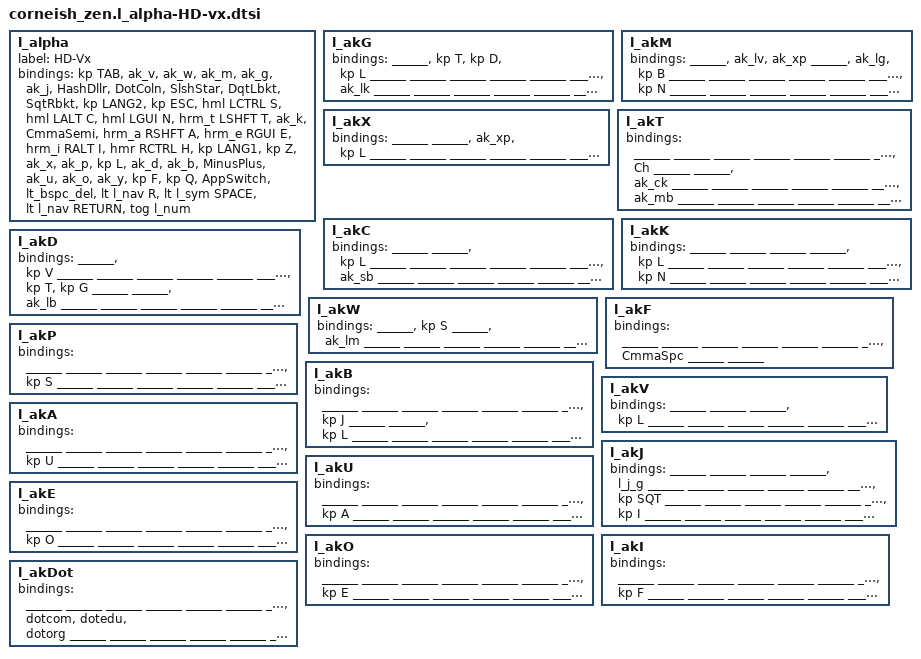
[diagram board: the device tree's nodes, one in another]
#define ______  &trans

/*  Base (alpha) Layer  Hands Down Vibranium-vb
        for 36 keys on a board with 42 keys
        ╭─────────────────────╮ ╭──────────────────────╮
esc     │  V   W   M   G   J  │ │  #$  .:  /*  "[  ']  │ LANG2/henk
tab     │  S   C   N   T   K  | |  ,;   A   E   I   H  │ LANG1/mhen
 Z      │  X   P   L   D   B  │ │  -+   U   O   Y   F  │  Q
        ╰────╮    App BSP  R  │ │  SPC RET Tg(Num)╭────╯
             ╰────────────────╯ ╰─────────────────╯
*/


                l_alpha {
                        label = "HD-Vx";
                        bindings = <
&kp TAB  &ak_v   &ak_w   &ak_m   &ak_g   &ak_j                          &HashDllr   &DotColn    &SlshStar   &DqtLbkt   &SqtRbkt &kp LANG2
&kp ESC &hml LCTRL S &hml LALT C   &hml LGUI N  &hrm_t LSHFT T &ak_k    &CmmaSemi   &hrm_a RSHFT A &hrm_e RGUI E  &hrm_i RALT I  &hmr RCTRL H &kp LANG1
&kp Z   &ak_x   &ak_p   &kp L   &ak_d   &ak_b                           &MinusPlus  &ak_u       &ak_o       &ak_y      &kp F    &kp Q
                        &AppSwitch &lt_bspc_del &lt l_nav R             &lt l_sym SPACE &lt l_nav RETURN  &tog l_num
                        >;
                };

                   l_akG {
                            bindings = <
______   &kp T    &kp D    &kp L    ______   ______       ______   ______   ______   ______   ______   ______
______   ______   ______   ______   ______   &ak_lk       ______   ______   ______   ______   ______   ______
______   ______   ______   ______   ______   ______       ______   ______   ______   ______   ______   ______
                           ______   ______   ______       ______   ______   ______
                            >;
                   };
                   l_akM {
                            bindings = <
______   &ak_lv   &ak_xp   ______   &ak_lg   &kp B        ______   ______   ______   ______   ______   ______
______   ______   ______   ______   ______   ______       ______   ______   ______   ______   &kp N    ______
______   ______   ______   ______   ______   ______       ______   ______   ______   ______   ______   ______
                           ______   ______   ______       ______   ______   ______
                            >;
                   };
                   l_akX {
                            bindings = <
______   ______   &ak_xp   &kp L    ______   ______       ______   ______   ______   ______   ______   ______
______   ______   ______   ______   ______   ______       ______   ______   ______   ______   ______   ______
______   ______   ______   ______   ______   ______       ______   ______   ______   ______   ______   ______
                           ______   ______   ______       ______   ______   ______
                            >;
                   };
                   l_akT {
                            bindings = <
______   ______   ______   ______   ______   ______       ______   ______   ______   ______   ______   ______
______   ______   &Ch      ______   ______   &ak_ck       ______   ______   ______   ______   ______   ______
______   ______   ______   ______   ______   &ak_mb       ______   ______   ______   ______   ______   ______
                           ______   ______   ______       ______   ______   ______
                            >;
                   };
                l_akC {
                        bindings = <
______   ______   &kp L    ______   ______   ______       ______   ______   ______   ______   ______   ______
______   ______   ______   ______   ______   ______       ______   ______   ______   ______   ______   ______
______   &ak_sb   ______   ______   ______   ______       ______   ______   ______   ______   ______   ______
                           ______   ______   ______       ______   ______   ______
                        >;
                };
                   l_akK {
                            bindings = <
______   ______   ______   ______   &kp L    ______       ______   ______   ______   ______   ______   ______
______   ______   ______   ______   &kp N    ______       ______   ______   ______   ______   ______   ______
______   ______   ______   ______   ______   ______       ______   ______   ______   ______   ______   ______
                           ______   ______   ______       ______   ______   ______
                            >;
                   };
                   l_akD {
                            bindings = <
______   &kp V    ______   ______   ______   ______       ______   ______   ______   ______   ______   ______
______   ______   ______   ______   ______   ______       ______   ______   ______   ______   ______   ______
______   &kp T    &kp G    ______   ______   &ak_lb       ______   ______   ______   ______   ______   ______
                           ______   ______   ______       ______   ______   ______
                            >;
                   };
                   l_akW {
                            bindings = <
______   &kp S    ______    &ak_lm  ______   ______       ______   ______   ______   ______   ______   ______
______   ______   ______   ______   ______   ______       ______   ______   ______   ______   ______   ______
______   ______   ______   ______   ______   ______       ______   ______   ______   ______   ______   ______
                           ______   ______   ______       ______   ______   ______
                            >;
                   };
                   l_akF {
                            bindings = <
______   ______   ______   ______   ______   ______       ______   ______   ______   ______   ______   ______
______   ______   ______   ______   ______   ______       ______   ______   ______   ______   ______   ______
______   ______   ______   ______   ______   ______       ______   ______   ______   ______   ______   ______
/*
______   &cc LS(V)  &cc LS(W)  &cc LS(M)  &cc LS(G)  &cc LS(J)      ______    ______     ______     ______     ______      ______
______   &cc LS(S)  &cc LS(C)  &cc LS(N)  &cc LS(T)  &cc LS(K)      &caps_word &cc LS(A)  &cc LS(E)  &cc LS(I)  &cc LS(H)   ______
______   &cc LS(X)  &cc LS(P)  &cc LS(L)  &cc LS(D)  &cc LS(B)      ______    &cc LS(U)  &cc LS(O)  &cc LS(Y)  &cc LS(F)   ______
*/
                               ______     ______     ______         &CmmaSpc  ______     ______
                            >;
                   };
                   l_akP {
                            bindings = <
______   ______   ______   ______   ______   ______       ______   ______   ______   ______   ______   ______
______   ______   ______   ______   ______   ______       ______   ______   ______   ______   ______   ______
______   &kp S    ______   ______   ______   ______       ______   ______   ______   ______   ______   ______
                           ______   ______   ______       ______   ______   ______
                            >;
                   };
                   l_akB {
                            bindings = <
______   ______   ______   ______   ______   ______       ______   ______   ______   ______   ______   ______
______   ______   ______   ______   ______   ______       ______   ______   ______   ______   ______   ______
______   &kp J    ______   ______   &kp L    ______       ______   ______   ______   ______   ______   ______
                           ______   ______   ______       ______   ______   ______
                            >;
                   };
                   l_akV {
                            bindings = <
______   ______   ______   &kp L    ______   ______       ______   ______   ______   ______   ______   ______
______   ______   ______   ______   ______   ______       ______   ______   ______   ______   ______   ______
______   ______   ______   ______   ______   ______       ______   ______   ______   ______   ______   ______
                           ______   ______   ______       ______   ______   ______
                            >;
                   };
                l_akJ {
                        bindings = <

______   ______   ______   ______   &l_j_g   ______       ______   ______   ______   ______   ______   ______
______   ______   ______   ______   ______   ______       ______   ______   ______   ______   &kp SQT  ______
______   ______   ______   ______   ______   ______       ______   ______   ______   ______   &kp I    ______
                           ______   ______   ______       ______   ______   ______
                        >;
                };



                   l_akA {
                            bindings = <
______   ______   ______   ______   ______   ______       ______   ______   ______   ______   &kp U    ______
______   ______   ______   ______   ______   ______       ______   ______   ______   ______   ______   ______
______   ______   ______   ______   ______   ______       ______   ______   ______   ______   ______   ______
                           ______   ______   ______       ______   ______   ______
                            >;
                   };

                   l_akU {
                            bindings = <
______   ______   ______   ______   ______   ______       ______   ______   ______   ______   &kp A    ______
______   ______   ______   ______   ______   ______       ______   ______   ______   ______   ______   ______
______   ______   ______   ______   ______   ______       ______   ______   ______   ______   ______   ______
                           ______   ______   ______       ______   ______   ______
                            >;
                   };

                   l_akE {
                            bindings = <
______   ______   ______   ______   ______   ______       ______   ______   ______   ______   ______   ______
______   ______   ______   ______   ______   ______       ______   ______   ______   ______   &kp O    ______
______   ______   ______   ______   ______   ______       ______   ______   ______   ______   ______   ______
                           ______   ______   ______       ______   ______   ______
                            >;
                   };
                   l_akO {
                            bindings = <
______   ______   ______   ______   ______   ______       ______   ______   ______   ______   &kp E    ______
______   ______   ______   ______   ______   ______       ______   ______   ______   ______   ______   ______
______   ______   ______   ______   ______   ______       ______   ______   ______   ______   ______   ______
                           ______   ______   ______       ______   ______   ______
                            >;
                   };
                   l_akI {
                            bindings = <
______   ______   ______   ______   ______   ______       ______   ______   ______   ______   ______   ______
______   ______   ______   ______   ______   ______       ______   ______   ______   ______   &kp F    ______
______   ______   ______   ______   ______   ______       ______   ______   ______   ______   ______   ______
                           ______   ______   ______       ______   ______   ______
                            >;
                   };

                   l_akDot {
                            bindings = <
______   ______   ______   ______   ______   ______       ______   ______   &dotcom  &dotedu &dotorg   ______
______   ______   ______   ______   ______   ______       ______   ______   ______   ______   ______   ______
______   ______   ______   ______   ______   ______       ______   ______   ______   ______   ______   ______
                           ______   ______   ______       ______   ______   ______
                            >;
                   };
